# ATmega128RFA1 register map
Vendor: Atmel; File version: 1.0
CPU: other r0p0, little endian, no MPU, no FPU, 4 interrupt priority bits
Registers are 8-bit, read-write, reset 0x0 unless marked. A register's access mark holds for its fields unless they carry their own. Offsets are from the block's base; [hi:lo] are bit positions; {n}, {i} and the like mark numbered series; 'fields as' and 'values as' point back to an identical list.

## EEPROM
Base 0x0080003F
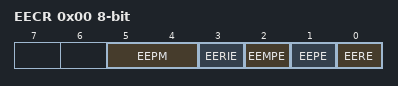
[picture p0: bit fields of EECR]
0x00 EECR — EEPROM Control Register
  [5:4] EEPM — EEPROM Programming Mode
    0=ERASE_AND_WRITE_IN_ONE_OPERATION_ATOMIC_OPERATION; 1=ERASE_ONLY; 2=WRITE_ONLY; 3=RESERVED_FOR_FUTURE_USE
  [3] EERIE — EEPROM Ready Interrupt Enable
  [2] EEMPE — EEPROM Master Write Enable
  [1] EEPE — EEPROM Programming Enable
  [0] EERE — EEPROM Read Enable
0x01 EEDR — EEPROM Data Register
0x02 EEAR 16-bit (reset mask 0xFF) — EEPROM Address Register Bytes

## EXINT — External Interrupts
Base 0x0080003B
0x00 PCIFR — Pin Change Interrupt Flag Register (read-only for debugger)
  [2:0] PCIF — Pin Change Interrupt Flags
0x01 EIFR — External Interrupt Flag Register (read-only for debugger)
  [7:0] INTF — External Interrupt Flag
    0=NO_EDGE_OR_LOGIC_CHANGE_ON_INT7_0_OCCURRED; 1=A_EDGE_OR_LOGIC_CHANGE_ON_INT0_OCCURRED_AND_TRIGGERED_AN_INTERRUPT_REQUEST; 128=A_EDGE_OR_LOGIC_CHANGE_ON_INT7_OCCURRED_AND_TRIGGERED_AN_INTERRUPT_REQUEST
0x02 EIMSK — External Interrupt Mask Register
  [7:0] INT — External Interrupt Request Enable
    0=ALL_EXTERNAL_PIN_INTERRUPTS_ARE_DISABLED; 255=ALL_EXTERNAL_PIN_INTERRUPTS_ARE_ENABLED
0x2D PCICR — Pin Change Interrupt Control Register
  [2:0] PCIE — Pin Change Interrupt Enables
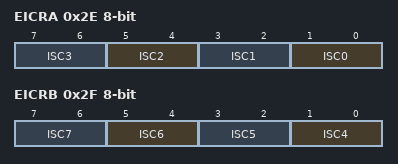
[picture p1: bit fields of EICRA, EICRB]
0x2E EICRA — External Interrupt Control Register A
  [all] fields
    0=THE_LOW_LEVEL_OF_INTN_GENERATES_AN_INTERRUPT_REQUEST; 1=ANY_EDGE_OF_INTN_GENERATES_ASYNCHRONOUSLY_AN_INTERRUPT_REQUEST; 2=THE_FALLING_EDGE_OF_INTN_GENERATES_ASYNCHRONOUSLY_AN_INTERRUPT_REQUEST; 3=THE_RISING_EDGE_OF_INTN_GENERATES_ASYNCHRONOUSLY_AN_INTERRUPT_REQUEST
  [2n+1:2n] ISC{n} (n=0..3) — External Interrupt {n} Sense Control Bit
0x2F EICRB — External Interrupt Control Register B
  [all] fields
    values as the fields of EICRA
  [2n-7:2n-8] ISC{n} (n=4..7) — External Interrupt {n} Sense Control Bit
0x30 PCMSK0 — Pin Change Mask Register 0
0x31 PCMSK1 — Pin Change Mask Register 1
  [7:0] PCINT — Pin Change Enable Mask
0x32 PCMSK2 — Pin Change Mask Register 2
  [7:0] PCINT — Pin Change Enable Mask

## FLASH — FLASH Controller
Base 0x00800067
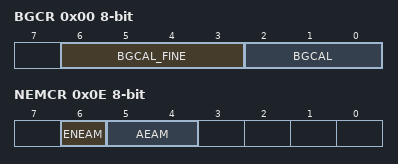
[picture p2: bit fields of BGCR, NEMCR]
0x00 BGCR — Reference Voltage Calibration Register
  [6:3] BGCAL_FINE — Fine Calibration Bits
    0=CENTER_VALUE; 1=VOLTAGE_STEP_UP; 7=SETTING_FOR_HIGHEST_VOLTAGE; 8=VOLTAGE_STEP_DOWN; 15=SETTING_FOR_LOWEST_VOLTAGE
  [2:0] BGCAL — Coarse Calibration Bits
    0=SETTING_FOR_HIGHEST_VOLTAGE; 3=VOLTAGE_STEP_UP; 4=CENTER_VALUE; 5=VOLTAGE_STEP_DOWN; 7=SETTING_FOR_LOWEST_VOLTAGE
0x0E NEMCR — Flash Extended-Mode Control-Register
  [6] ENEAM — Enable Extended Address Mode for Extra Rows
  [5:4] AEAM — Address for Extended Address Mode of Extra Rows
    0=FACTORY_ROW; 1=USER_ROW_1; 2=USER_ROW_2; 3=USER_ROW_3

## FUSE — Fuses
Base 0x00800000
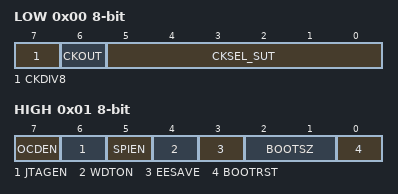
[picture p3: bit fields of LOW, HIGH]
0x00 LOW
  [7] CKDIV8 — Divide clock by 8 internally
  [6] CKOUT — Clock output on PORTE7
  [5:0] CKSEL_SUT — Select Clock Source : Start-up time
    0=EXTCLK_6CK_0MS (Ext. Clock; Start-up time: 6 CK + 0 ms); 2=INTRCOSC_6CK_0MS (Int. RC Osc.; Start-up time: 6 CK + 0 ms); 3=INTRCOSC_128KHZ_6CK_0MS (Int. 128kHz RC Osc.; Start-up time: 6 CK + 0 ms); 6=TRXOSC_258CK_4MS1 (Transceiver Oscillator; Start-up time: 258 CK + 4.1 ms); 7=TRXOSC_1KCK_65MS (Transceiver Oscillator; Start-up time: 1K CK + 65 ms); 16=EXTCLK_6CK_4MS1 (Ext. Clock; Start-up time: 6 CK + 4.1 ms); 18=INTRCOSC_6CK_4MS1 (Int. RC Osc.; Start-up time: 6 CK + 4.1 ms); 19=INTRCOSC_128KHZ_6CK_4MS1 (Int. 128kHz RC Osc.; Start-up time: 6 CK + 4.1 ms); 22=TRXOSC_258CK_65MS (Transceiver Oscillator; Start-up time: 258 CK + 65 ms); 23=TRXOSC_16KCK_0MS (Transceiver Oscillator; Start-up time: 16K CK + 0 ms); 32=EXTCLK_6CK_65MS (Ext. Clock; Start-up time: 6 CK + 65 ms); 34=INTRCOSC_6CK_65MS (Int. RC Osc.; Start-up time: 6 CK + 65 ms); 35=INTRCOSC_128KHZ_6CK_65MS (Int. 128kHz RC Osc.; Start-up time: 6 CK + 65 ms); 38=TRXOSC_1KCK_0MS (Transceiver Oscillator; Start-up time: 1K CK + 0 ms); 39=TRXOSC_16KCK_4MS1 (Transceiver Oscillator; Start-up time: 16K CK + 4.1 ms); 54=TRXOSC_1KCK_4MS1 (Transceiver Oscillator; Start-up time: 1K CK + 4.1 ms); 55=TRXOSC_16KCK_65MS (Transceiver Oscillator; Start-up time: 16K CK + 65 ms)
0x01 HIGH
  [7] OCDEN — On-Chip Debug Enabled
  [6] JTAGEN — JTAG Interface Enabled
  [5] SPIEN — Serial program downloading (SPI) enabled
  [4] WDTON — Watchdog timer always on
  [3] EESAVE — Preserve EEPROM through the Chip Erase cycle
  [2:1] BOOTSZ — Select Boot Size
    0=4096W_F000 (Boot Flash size=4096 words start address=$F000); 1=2048W_F800 (Boot Flash size=2048 words start address=$F800); 2=1024W_FC00 (Boot Flash size=1024 words start address=$FC00); 3=512W_FE00 (Boot Flash size=512 words start address=$FE00)
  [0] BOOTRST — Boot Reset vector Enabled
0x02 EXTENDED
  [2:0] BODLEVEL — Brown-out Detector trigger level
    0=2V4 (Brown-out detection at VCC=2.4 V); 1=2V3 (Brown-out detection at VCC=2.3 V); 2=2V2 (Brown-out detection at VCC=2.2 V); 3=2V1 (Brown-out detection at VCC=2.1 V); 4=2V0 (Brown-out detection at VCC=2.0 V); 5=1V9 (Brown-out detection at VCC=1.9 V); 6=1V8 (Brown-out detection at VCC=1.8 V); 7=DISABLED (Brown-out detection disabled)
